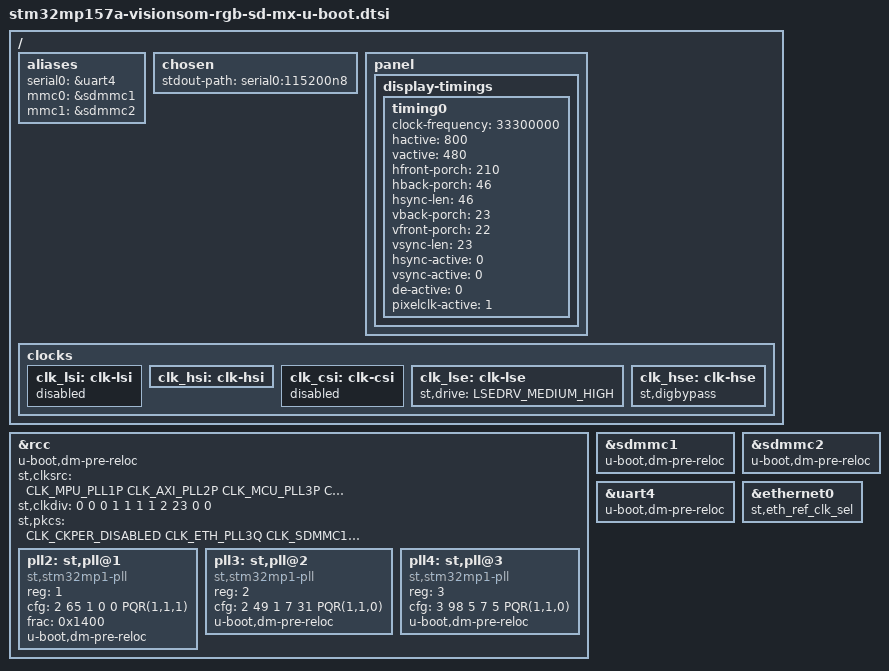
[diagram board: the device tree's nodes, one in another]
/* SPDX-License-Identifier: GPL-2.0+ OR BSD-3-Clause*/
/*
 * Copyright (C) 2021, STMicroelectronics - All Rights Reserved
 * Author: STM32CubeMX code generation for STMicroelectronics.
 */

/* For more information on Device Tree configuration, please refer to
 * https://wiki.st.com/stm32mpu/wiki/Category:Device_tree_configuration
 */

#include <dt-bindings/clock/stm32mp1-clksrc.h>
#include "stm32mp15-mx.dtsi"

#include "stm32mp15-u-boot.dtsi"
#include "stm32mp15-ddr.dtsi"

/* USER CODE BEGIN includes */
/* USER CODE END includes */

/ {

	/* USER CODE BEGIN root */
	aliases {
		serial0 = &uart4;
		mmc0 = &sdmmc1;
		mmc1 = &sdmmc2;
	};

	chosen {
		stdout-path = "serial0:115200n8";
	};

	panel {
                display-timings {
                        timing0: timing0 {
                                clock-frequency = <33300000>;
                                hactive = <800>;
                                vactive = <480>;
                                hfront-porch = <210>;
                                hback-porch = <46>;
                                hsync-len = <46>;
                                vback-porch = <23>;
                                vfront-porch = <22>;
                                vsync-len = <23>;
                                hsync-active = <0>;
                                vsync-active = <0>;
                                de-active = <0>;
                                pixelclk-active = <1>;
                        };
                };
	};

	/* USER CODE END root */

	clocks {
		/* USER CODE BEGIN clocks */
		/* USER CODE END clocks */

#ifndef CONFIG_TFABOOT
		clk_lsi: clk-lsi {
			status = "disabled";

			/* USER CODE BEGIN clk_lsi */
			/* USER CODE END clk_lsi */
		};
		clk_hsi: clk-hsi {

			/* USER CODE BEGIN clk_hsi */
			/* USER CODE END clk_hsi */
		};
		clk_csi: clk-csi {
			status = "disabled";

			/* USER CODE BEGIN clk_csi */
			/* USER CODE END clk_csi */
		};
		clk_lse: clk-lse {
			st,drive = < LSEDRV_MEDIUM_HIGH >;

			/* USER CODE BEGIN clk_lse */
			/* USER CODE END clk_lse */
		};
		clk_hse: clk-hse {
			st,digbypass;

			/* USER CODE BEGIN clk_hse */
			/* USER CODE END clk_hse */
		};
#endif	/*CONFIG_TFABOOT*/
	};

}; /*root*/

#ifndef CONFIG_TFABOOT

&rcc {
	u-boot,dm-pre-reloc;
	st,clksrc = <
		CLK_MPU_PLL1P
		CLK_AXI_PLL2P
		CLK_MCU_PLL3P
		CLK_PLL12_HSE
		CLK_PLL3_HSE
		CLK_PLL4_HSE
		CLK_RTC_LSE
		CLK_MCO1_DISABLED
		CLK_MCO2_DISABLED
	>;
	st,clkdiv = <
		0 		/*MPU*/
		0 		/*AXI*/
		0 		/*MCU*/
		1 		/*APB1*/
		1 		/*APB2*/
		1 		/*APB3*/
		1 		/*APB4*/
		2 		/*APB5*/
		23 		/*RTC*/
		0 		/*MCO1*/
		0 		/*MCO2*/
	>;
	st,pkcs = <
		CLK_CKPER_DISABLED
		CLK_ETH_PLL3Q
		CLK_SDMMC12_PLL4P
		CLK_STGEN_HSI
		CLK_USBPHY_HSE
		CLK_SPI2S1_DISABLED
		CLK_SPI2S23_DISABLED
		CLK_SPI45_DISABLED
		CLK_SPI6_DISABLED
		CLK_I2C46_PCLK5
		CLK_SDMMC3_PLL4P
		CLK_USBO_USBPHY
		CLK_ADC_DISABLED
		CLK_CEC_DISABLED
		CLK_I2C12_DISABLED
		CLK_I2C35_DISABLED
		CLK_UART1_DISABLED
		CLK_UART24_PCLK1
		CLK_UART35_DISABLED
		CLK_UART6_DISABLED
		CLK_UART78_PCLK1
		CLK_SPDIF_DISABLED
		CLK_SAI1_DISABLED
		CLK_SAI2_DISABLED
		CLK_SAI3_DISABLED
		CLK_SAI4_DISABLED
		CLK_LPTIM1_DISABLED
		CLK_LPTIM23_DISABLED
		CLK_LPTIM45_DISABLED
	>;
	pll2:st,pll@1 {
		compatible = "st,stm32mp1-pll";
		reg = <1>;
		cfg = < 2 65 1 0 0 PQR(1,1,1) >;
		frac = < 0x1400 >;
		u-boot,dm-pre-reloc;
	};
	pll3:st,pll@2 {
		compatible = "st,stm32mp1-pll";
		reg = <2>;
		cfg = < 2 49 1 7 31 PQR(1,1,0) >;
		u-boot,dm-pre-reloc;
	};
	pll4:st,pll@3 {
		compatible = "st,stm32mp1-pll";
		reg = <3>;
		cfg = < 3 98 5 7 5 PQR(1,1,0) >;
		u-boot,dm-pre-reloc;
	};
};

&sdmmc1{
	u-boot,dm-pre-reloc;

	/* USER CODE BEGIN sdmmc1 */
	/* USER CODE END sdmmc1 */
};

&sdmmc2{
	u-boot,dm-pre-reloc;

	/* USER CODE BEGIN sdmmc2 */
	/* USER CODE END sdmmc2 */
};

#endif	/*CONFIG_TFABOOT*/

&uart4{
	u-boot,dm-pre-reloc;

	/* USER CODE BEGIN uart4 */
	/* USER CODE END uart4 */
};

/* USER CODE BEGIN addons */

&ethernet0{
        st,eth_ref_clk_sel;
};

/* USER CODE END addons */

